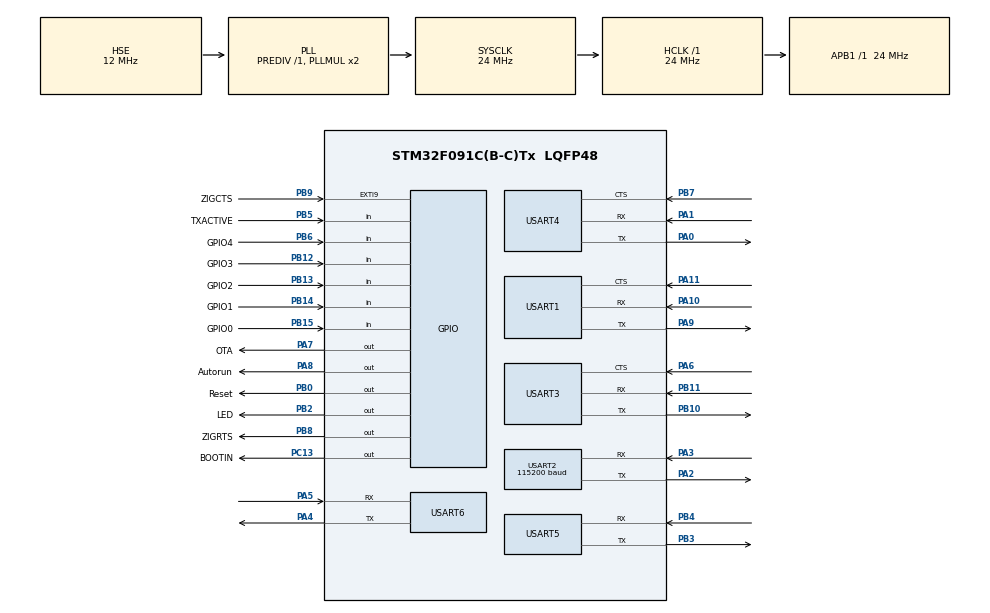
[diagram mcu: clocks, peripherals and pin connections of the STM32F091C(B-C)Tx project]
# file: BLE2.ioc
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Dma.Request0=USART1_RX
Dma.Request1=USART2_RX
Dma.Request10=USART3_TX
Dma.Request11=USART4_TX
Dma.Request2=USART3_RX
Dma.Request3=USART6_RX
Dma.Request4=USART5_RX
Dma.Request5=USART4_RX
Dma.Request6=USART6_TX
Dma.Request7=USART5_TX
Dma.Request8=USART1_TX
Dma.Request9=USART2_TX
Dma.USART1_RX.0.Direction=DMA_PERIPH_TO_MEMORY
Dma.USART1_RX.0.Instance=DMA1_Channel1
Dma.USART1_RX.0.MemDataAlignment=DMA_MDATAALIGN_BYTE
Dma.USART1_RX.0.MemInc=DMA_MINC_ENABLE
Dma.USART1_RX.0.Mode=DMA_CIRCULAR
Dma.USART1_RX.0.PeriphDataAlignment=DMA_PDATAALIGN_BYTE
Dma.USART1_RX.0.PeriphInc=DMA_PINC_DISABLE
Dma.USART1_RX.0.Priority=DMA_PRIORITY_LOW
Dma.USART1_TX.8.Direction=DMA_MEMORY_TO_PERIPH
Dma.USART1_TX.8.Instance=DMA1_Channel7
Dma.USART1_TX.8.MemDataAlignment=DMA_MDATAALIGN_BYTE
Dma.USART1_TX.8.MemInc=DMA_MINC_ENABLE
Dma.USART1_TX.8.Mode=DMA_NORMAL
Dma.USART1_TX.8.PeriphDataAlignment=DMA_PDATAALIGN_BYTE
Dma.USART1_TX.8.PeriphInc=DMA_PINC_DISABLE
Dma.USART1_TX.8.Priority=DMA_PRIORITY_LOW
Dma.USART2_RX.1.Direction=DMA_PERIPH_TO_MEMORY
Dma.USART2_RX.1.Instance=DMA1_Channel3
Dma.USART2_RX.1.MemDataAlignment=DMA_MDATAALIGN_BYTE
Dma.USART2_RX.1.MemInc=DMA_MINC_ENABLE
Dma.USART2_RX.1.Mode=DMA_CIRCULAR
Dma.USART2_RX.1.PeriphDataAlignment=DMA_PDATAALIGN_BYTE
Dma.USART2_RX.1.PeriphInc=DMA_PINC_DISABLE
Dma.USART2_RX.1.Priority=DMA_PRIORITY_LOW
Dma.USART2_TX.9.Direction=DMA_MEMORY_TO_PERIPH
Dma.USART2_TX.9.Instance=DMA2_Channel1
Dma.USART2_TX.9.MemDataAlignment=DMA_MDATAALIGN_BYTE
Dma.USART2_TX.9.MemInc=DMA_MINC_ENABLE
Dma.USART2_TX.9.Mode=DMA_NORMAL
Dma.USART2_TX.9.PeriphDataAlignment=DMA_PDATAALIGN_BYTE
Dma.USART2_TX.9.PeriphInc=DMA_PINC_DISABLE
Dma.USART2_TX.9.Priority=DMA_PRIORITY_LOW
Dma.USART3_RX.2.Direction=DMA_PERIPH_TO_MEMORY
Dma.USART3_RX.2.Instance=DMA1_Channel5
Dma.USART3_RX.2.MemDataAlignment=DMA_MDATAALIGN_BYTE
Dma.USART3_RX.2.MemInc=DMA_MINC_ENABLE
Dma.USART3_RX.2.Mode=DMA_CIRCULAR
Dma.USART3_RX.2.PeriphDataAlignment=DMA_PDATAALIGN_BYTE
Dma.USART3_RX.2.PeriphInc=DMA_PINC_DISABLE
Dma.USART3_RX.2.Priority=DMA_PRIORITY_LOW
Dma.USART3_TX.10.Direction=DMA_MEMORY_TO_PERIPH
Dma.USART3_TX.10.Instance=DMA2_Channel4
Dma.USART3_TX.10.MemDataAlignment=DMA_MDATAALIGN_BYTE
Dma.USART3_TX.10.MemInc=DMA_MINC_ENABLE
Dma.USART3_TX.10.Mode=DMA_NORMAL
Dma.USART3_TX.10.PeriphDataAlignment=DMA_PDATAALIGN_BYTE
Dma.USART3_TX.10.PeriphInc=DMA_PINC_DISABLE
Dma.USART3_TX.10.Priority=DMA_PRIORITY_LOW
Dma.USART4_RX.5.Direction=DMA_PERIPH_TO_MEMORY
Dma.USART4_RX.5.Instance=DMA2_Channel3
Dma.USART4_RX.5.MemDataAlignment=DMA_MDATAALIGN_BYTE
Dma.USART4_RX.5.MemInc=DMA_MINC_ENABLE
Dma.USART4_RX.5.Mode=DMA_CIRCULAR
Dma.USART4_RX.5.PeriphDataAlignment=DMA_PDATAALIGN_BYTE
Dma.USART4_RX.5.PeriphInc=DMA_PINC_DISABLE
Dma.USART4_RX.5.Priority=DMA_PRIORITY_LOW
Dma.USART4_TX.11.Direction=DMA_MEMORY_TO_PERIPH
Dma.USART4_TX.11.Instance=DMA2_Channel5
Dma.USART4_TX.11.MemDataAlignment=DMA_MDATAALIGN_BYTE
Dma.USART4_TX.11.MemInc=DMA_MINC_ENABLE
Dma.USART4_TX.11.Mode=DMA_NORMAL
Dma.USART4_TX.11.PeriphDataAlignment=DMA_PDATAALIGN_BYTE
Dma.USART4_TX.11.PeriphInc=DMA_PINC_DISABLE
Dma.USART4_TX.11.Priority=DMA_PRIORITY_LOW
Dma.USART5_RX.4.Direction=DMA_PERIPH_TO_MEMORY
Dma.USART5_RX.4.Instance=DMA2_Channel2
Dma.USART5_RX.4.MemDataAlignment=DMA_MDATAALIGN_BYTE
Dma.USART5_RX.4.MemInc=DMA_MINC_ENABLE
Dma.USART5_RX.4.Mode=DMA_CIRCULAR
Dma.USART5_RX.4.PeriphDataAlignment=DMA_PDATAALIGN_BYTE
Dma.USART5_RX.4.PeriphInc=DMA_PINC_DISABLE
Dma.USART5_RX.4.Priority=DMA_PRIORITY_LOW
Dma.USART5_TX.7.Direction=DMA_MEMORY_TO_PERIPH
Dma.USART5_TX.7.Instance=DMA1_Channel4
Dma.USART5_TX.7.MemDataAlignment=DMA_MDATAALIGN_BYTE
Dma.USART5_TX.7.MemInc=DMA_MINC_ENABLE
Dma.USART5_TX.7.Mode=DMA_NORMAL
Dma.USART5_TX.7.PeriphDataAlignment=DMA_PDATAALIGN_BYTE
Dma.USART5_TX.7.PeriphInc=DMA_PINC_DISABLE
Dma.USART5_TX.7.Priority=DMA_PRIORITY_LOW
Dma.USART6_RX.3.Direction=DMA_PERIPH_TO_MEMORY
Dma.USART6_RX.3.Instance=DMA1_Channel6
Dma.USART6_RX.3.MemDataAlignment=DMA_MDATAALIGN_BYTE
Dma.USART6_RX.3.MemInc=DMA_MINC_ENABLE
Dma.USART6_RX.3.Mode=DMA_CIRCULAR
Dma.USART6_RX.3.PeriphDataAlignment=DMA_PDATAALIGN_BYTE
Dma.USART6_RX.3.PeriphInc=DMA_PINC_DISABLE
Dma.USART6_RX.3.Priority=DMA_PRIORITY_LOW
Dma.USART6_TX.6.Direction=DMA_MEMORY_TO_PERIPH
Dma.USART6_TX.6.Instance=DMA1_Channel2
Dma.USART6_TX.6.MemDataAlignment=DMA_MDATAALIGN_BYTE
Dma.USART6_TX.6.MemInc=DMA_MINC_ENABLE
Dma.USART6_TX.6.Mode=DMA_NORMAL
Dma.USART6_TX.6.PeriphDataAlignment=DMA_PDATAALIGN_BYTE
Dma.USART6_TX.6.PeriphInc=DMA_PINC_DISABLE
Dma.USART6_TX.6.Priority=DMA_PRIORITY_LOW
Mcu.Family=STM32F0
Mcu.Name=STM32F091C(B-C)Tx
Mcu.Package=LQFP48
NVIC.DMA1_Ch1_IRQn=true\:0\:0\:false\:false\:true\:true
NVIC.DMA1_Ch2_3_DMA2_Ch1_2_IRQn=true\:0\:0\:false\:false\:true\:true
NVIC.DMA1_Ch4_7_DMA2_Ch3_5_IRQn=true\:0\:0\:false\:false\:true\:true
NVIC.USART1_IRQn=true\:0\:0\:false\:false\:true\:true
NVIC.USART2_IRQn=true\:0\:0\:false\:false\:true\:true
NVIC.USART3_8_IRQn=true\:0\:0\:false\:false\:true\:true
PA0.Mode=Asynchronous
PA0.Signal=USART4_TX
PA1.Mode=Asynchronous
PA1.Signal=USART4_RX
PA10.Mode=Asynchronous
PA10.Signal=USART1_RX
PA11.Mode=CTS_Only
PA11.Signal=USART1_CTS
PA13.Mode=Serial_Wire
PA13.Signal=SYS_SWDIO
PA14.Mode=Serial_Wire
PA14.Signal=SYS_SWCLK
PA2.Mode=Asynchronous
PA2.Signal=USART2_TX
PA3.Mode=Asynchronous
PA3.Signal=USART2_RX
PA4.Mode=Asynchronous
PA4.Signal=USART6_TX
PA5.Mode=Asynchronous
PA5.Signal=USART6_RX
PA6.Mode=CTS_Only
PA6.Signal=USART3_CTS
PA7.GPIO_Label=OTA
PA7.Signal=GPIO_Output
PA8.GPIO_Label=Autorun
PA8.Signal=GPIO_Output
PA9.Mode=Asynchronous
PA9.Signal=USART1_TX
PB0.GPIO_Label=Reset
PB0.Signal=GPIO_Output
PB10.Mode=Asynchronous
PB10.Signal=USART3_TX
PB11.Mode=Asynchronous
PB11.Signal=USART3_RX
PB12.GPIO_Label=GPIO3
PB12.Signal=GPIO_Input
PB13.GPIO_Label=GPIO2
PB13.Signal=GPIO_Input
PB14.GPIO_Label=GPIO1
PB14.Signal=GPIO_Input
PB15.GPIO_Label=GPIO0
PB15.Signal=GPIO_Input
PB2.GPIO_Label=LED
PB2.Signal=GPIO_Output
PB3.Mode=Asynchronous
PB3.Signal=USART5_TX
PB4.Mode=Asynchronous
PB4.Signal=USART5_RX
PB5.GPIO_Label=TXACTIVE
PB5.Signal=GPIO_Input
PB6.GPIO_Label=GPIO4
PB6.Signal=GPIO_Input
PB7.Mode=CTS_Only
PB7.Signal=USART4_CTS
PB8.GPIO_Label=ZIGRTS
PB8.Signal=GPIO_Output
PB9.GPIO_Label=ZIGCTS
PB9.Signal=GPXTI9
PC13.GPIO_Label=BOOTIN
PC13.Signal=GPIO_Output
PF0-OSC_IN.Mode=HSE-External-Oscillator
PF0-OSC_IN.Signal=RCC_OSC_IN
PF1-OSC_OUT.Mode=HSE-External-Oscillator
PF1-OSC_OUT.Signal=RCC_OSC_OUT
PF11BOOT0.Signal=GPIO_Input
ProjectManager.HeapSize=0x200
ProjectManager.StackSize=0x400
ProjectManager.TargetToolchain=MDK-ARM V5
RCC.AHBFreq_Value=24000000
RCC.APB1Freq_Value=24000000
RCC.APB1TimFreq_Value=24000000
RCC.HCLKFreq_Value=24000000
RCC.HSE_VALUE=12000000
RCC.PLLSourceVirtual=RCC_PLLSOURCE_HSE
RCC.SYSCLKFreq_VALUE=24000000
RCC.SYSCLKSource=RCC_SYSCLKSOURCE_PLLCLK
USART1.VirtualMode-Asynchronous=VM_ASYNC
USART2.BaudRate=115200
USART2.VirtualMode-Asynchronous=VM_ASYNC
USART3.VirtualMode-Asynchronous=VM_ASYNC
USART4.VirtualMode-Asynchronous=VM_ASYNC
USART5.VirtualMode-Asynchronous=VM_ASYNC
USART6.VirtualMode=VM_ASYNC
VP_RTC_VS_RTC_Activate.Mode=RTC_Enabled
board=custom

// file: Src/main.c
/* USER CODE BEGIN Header */
/**
  ******************************************************************************
  * @file           : main.c
  * @brief          : Main program body
  ******************************************************************************
  ** This notice applies to any and all portions of this file
  * that are not between comment pairs USER CODE BEGIN and
  * USER CODE END. Other portions of this file, whether
  * inserted by the user or by software development tools
  * are owned by their respective copyright owners.
  *
  * COPYRIGHT(c) 2018 STMicroelectronics
  *
  * Redistribution and use in source and binary forms, with or without modification,
  * are permitted provided that the following conditions are met:
  *   1. Redistributions of source code must retain the above copyright notice,
  *      this list of conditions and the following disclaimer.
  *   2. Redistributions in binary form must reproduce the above copyright notice,
  *      this list of conditions and the following disclaimer in the documentation
  *      and/or other materials provided with the distribution.
  *   3. Neither the name of STMicroelectronics nor the names of its contributors
  *      may be used to endorse or promote products derived from this software
  *      without specific prior written permission.
  *
  * THIS SOFTWARE IS PROVIDED BY THE COPYRIGHT HOLDERS AND CONTRIBUTORS "AS IS"
  * AND ANY EXPRESS OR IMPLIED WARRANTIES, INCLUDING, BUT NOT LIMITED TO, THE
  * IMPLIED WARRANTIES OF MERCHANTABILITY AND FITNESS FOR A PARTICULAR PURPOSE ARE
  * DISCLAIMED. IN NO EVENT SHALL THE COPYRIGHT HOLDER OR CONTRIBUTORS BE LIABLE
  * FOR ANY DIRECT, INDIRECT, INCIDENTAL, SPECIAL, EXEMPLARY, OR CONSEQUENTIAL
  * DAMAGES (INCLUDING, BUT NOT LIMITED TO, PROCUREMENT OF SUBSTITUTE GOODS OR
  * SERVICES; LOSS OF USE, DATA, OR PROFITS; OR BUSINESS INTERRUPTION) HOWEVER
  * CAUSED AND ON ANY THEORY OF LIABILITY, WHETHER IN CONTRACT, STRICT LIABILITY,
  * OR TORT (INCLUDING NEGLIGENCE OR OTHERWISE) ARISING IN ANY WAY OUT OF THE USE
  * OF THIS SOFTWARE, EVEN IF ADVISED OF THE POSSIBILITY OF SUCH DAMAGE.
  *
  ******************************************************************************
  */
/* USER CODE END Header */

#include "main.h"

/* USER CODE BEGIN Includes */
#include <stdbool.h>
#include <string.h>
#include "BLE.h"
#include "ZigBee.h"
#include "ServiceUartIF.h"

#pragma anon_unions
/* USER CODE END Includes */

RTC_HandleTypeDef hrtc;

UART_HandleTypeDef huart1;
UART_HandleTypeDef huart2;
UART_HandleTypeDef huart3;
UART_HandleTypeDef huart4;
UART_HandleTypeDef huart5;
UART_HandleTypeDef huart6;
DMA_HandleTypeDef hdma_usart1_rx;
DMA_HandleTypeDef hdma_usart1_tx;
DMA_HandleTypeDef hdma_usart2_rx;
DMA_HandleTypeDef hdma_usart2_tx;
DMA_HandleTypeDef hdma_usart3_rx;
DMA_HandleTypeDef hdma_usart3_tx;
DMA_HandleTypeDef hdma_usart4_rx;
DMA_HandleTypeDef hdma_usart4_tx;
DMA_HandleTypeDef hdma_usart5_rx;
DMA_HandleTypeDef hdma_usart5_tx;
DMA_HandleTypeDef hdma_usart6_rx;
DMA_HandleTypeDef hdma_usart6_tx;

void SystemClock_Config(void);
static void MX_GPIO_Init(void);
static void MX_DMA_Init(void);
static void MX_RTC_Init(void);
static void MX_USART1_UART_Init(void);
static void MX_USART2_UART_Init(void);
static void MX_USART3_UART_Init(void);
static void MX_USART4_UART_Init(void);
static void MX_USART5_UART_Init(void);
static void MX_USART6_UART_Init(void);

/* USER CODE BEGIN 0 */

//#define BUFFER_SIZE 256  /* must be power of two */
#define TX_BUFFER_SIZE 1024
//#define COMMAND_BUFFER_SIZE 128

void HAL_UART_ErrorCallback(UART_HandleTypeDef *huart)
{
    if(huart == &huart3)
    {
        if(huart->ErrorCode == HAL_UART_ERROR_FE)
        {
            __HAL_UART_CLEAR_FEFLAG(huart);
        }
    }

    if(huart == &huart2)
    {
        if(huart->ErrorCode == HAL_UART_ERROR_FE)
        {
            __HAL_UART_CLEAR_FEFLAG(huart);
        }
        ZigBeeReinitializeDMA();
    }
}

/* USER CODE END 0 */

int main(void)
{

  /* MCU Configuration--------------------------------------------------------*/

  /* Reset of all peripherals, Initializes the Flash interface and the Systick. */
  HAL_Init();

  /* Configure the system clock */
  SystemClock_Config();

  /* Initialize all configured peripherals */
  MX_GPIO_Init();
  MX_DMA_Init();
  MX_RTC_Init();
  MX_USART1_UART_Init();
  MX_USART2_UART_Init();
  MX_USART3_UART_Init();
  MX_USART4_UART_Init();
  MX_USART5_UART_Init();
  MX_USART6_UART_Init();
  /* USER CODE BEGIN 2 */

  HAL_GPIO_WritePin(BOOTIN_GPIO_Port, BOOTIN_Pin, GPIO_PIN_SET);    //do not boot in bootloader mode (RTX357)

  HAL_Delay(200);

  HAL_GPIO_WritePin(LED_GPIO_Port, LED_Pin, GPIO_PIN_SET);
  HAL_GPIO_WritePin(Reset_GPIO_Port, Reset_Pin, GPIO_PIN_SET);

  HAL_Delay(200);

  ServiceUartIFInit(&huart6);
  ZigBeeInit(&huart2);
  BleInit(&huart3, &huart1, &huart4, &huart5);

  /* USER CODE END 2 */

  /* Infinite loop */
  /* USER CODE BEGIN WHILE */
  //QueueItem *qi;

  while (1)
  {
    /* USER CODE END WHILE */

    /* USER CODE BEGIN 3 */
      BleTask();
      ZigBeeTask();
      ServiceUartIFTask();

  }
  /* USER CODE END 3 */
}

void SystemClock_Config(void)
{
  RCC_OscInitTypeDef RCC_OscInitStruct = {0};
  RCC_ClkInitTypeDef RCC_ClkInitStruct = {0};
  RCC_PeriphCLKInitTypeDef PeriphClkInit = {0};

  /**Initializes the CPU, AHB and APB busses clocks
  */
  RCC_OscInitStruct.OscillatorType = RCC_OSCILLATORTYPE_LSI|RCC_OSCILLATORTYPE_HSE;
  RCC_OscInitStruct.HSEState = RCC_HSE_ON;
  RCC_OscInitStruct.LSIState = RCC_LSI_ON;
  RCC_OscInitStruct.PLL.PLLState = RCC_PLL_ON;
  RCC_OscInitStruct.PLL.PLLSource = RCC_PLLSOURCE_HSE;
  RCC_OscInitStruct.PLL.PLLMUL = RCC_PLL_MUL2;
  RCC_OscInitStruct.PLL.PREDIV = RCC_PREDIV_DIV1;
  if (HAL_RCC_OscConfig(&RCC_OscInitStruct) != HAL_OK)
  {
    Error_Handler();
  }
  /**Initializes the CPU, AHB and APB busses clocks
  */
  RCC_ClkInitStruct.ClockType = RCC_CLOCKTYPE_HCLK|RCC_CLOCKTYPE_SYSCLK
                              |RCC_CLOCKTYPE_PCLK1;
  RCC_ClkInitStruct.SYSCLKSource = RCC_SYSCLKSOURCE_PLLCLK;
  RCC_ClkInitStruct.AHBCLKDivider = RCC_SYSCLK_DIV1;
  RCC_ClkInitStruct.APB1CLKDivider = RCC_HCLK_DIV1;

  if (HAL_RCC_ClockConfig(&RCC_ClkInitStruct, FLASH_LATENCY_0) != HAL_OK)
  {
    Error_Handler();
  }
  PeriphClkInit.PeriphClockSelection = RCC_PERIPHCLK_USART3|RCC_PERIPHCLK_USART1
                              |RCC_PERIPHCLK_USART2|RCC_PERIPHCLK_RTC;
  PeriphClkInit.Usart1ClockSelection = RCC_USART1CLKSOURCE_PCLK1;
  PeriphClkInit.Usart2ClockSelection = RCC_USART2CLKSOURCE_PCLK1;
  PeriphClkInit.Usart3ClockSelection = RCC_USART3CLKSOURCE_PCLK1;
  PeriphClkInit.RTCClockSelection = RCC_RTCCLKSOURCE_LSI;
  if (HAL_RCCEx_PeriphCLKConfig(&PeriphClkInit) != HAL_OK)
  {
    Error_Handler();
  }
}

static void MX_RTC_Init(void)
{

  /**Initialize RTC Only
  */
  hrtc.Instance = RTC;
  hrtc.Init.HourFormat = RTC_HOURFORMAT_24;
  hrtc.Init.AsynchPrediv = 127;
  hrtc.Init.SynchPrediv = 255;
  hrtc.Init.OutPut = RTC_OUTPUT_DISABLE;
  hrtc.Init.OutPutPolarity = RTC_OUTPUT_POLARITY_HIGH;
  hrtc.Init.OutPutType = RTC_OUTPUT_TYPE_OPENDRAIN;
  if (HAL_RTC_Init(&hrtc) != HAL_OK)
  {
    Error_Handler();
  }

}

static void MX_USART1_UART_Init(void)
{

  huart1.Instance = USART1;
  huart1.Init.BaudRate = 115200;
  huart1.Init.WordLength = UART_WORDLENGTH_8B;
  huart1.Init.StopBits = UART_STOPBITS_1;
  huart1.Init.Parity = UART_PARITY_NONE;
  huart1.Init.Mode = UART_MODE_TX_RX;
  huart1.Init.HwFlowCtl = UART_HWCONTROL_CTS;
  huart1.Init.OverSampling = UART_OVERSAMPLING_16;
  huart1.Init.OneBitSampling = UART_ONE_BIT_SAMPLE_DISABLE;
  huart1.AdvancedInit.AdvFeatureInit = UART_ADVFEATURE_NO_INIT;
  if (HAL_UART_Init(&huart1) != HAL_OK)
  {
    Error_Handler();
  }

}

static void MX_USART2_UART_Init(void)
{

  huart2.Instance = USART2;
  huart2.Init.BaudRate = 115200;
  huart2.Init.WordLength = UART_WORDLENGTH_8B;
  huart2.Init.StopBits = UART_STOPBITS_1;
  huart2.Init.Parity = UART_PARITY_NONE;
  huart2.Init.Mode = UART_MODE_TX_RX;
  huart2.Init.HwFlowCtl = UART_HWCONTROL_NONE;
  huart2.Init.OverSampling = UART_OVERSAMPLING_16;
  huart2.Init.OneBitSampling = UART_ONE_BIT_SAMPLE_DISABLE;
  huart2.AdvancedInit.AdvFeatureInit = UART_ADVFEATURE_NO_INIT;
  if (HAL_UART_Init(&huart2) != HAL_OK)
  {
    Error_Handler();
  }

}

static void MX_USART3_UART_Init(void)
{

  huart3.Instance = USART3;
  huart3.Init.BaudRate = 115200;
  huart3.Init.WordLength = UART_WORDLENGTH_8B;
  huart3.Init.StopBits = UART_STOPBITS_1;
  huart3.Init.Parity = UART_PARITY_NONE;
  huart3.Init.Mode = UART_MODE_TX_RX;
  huart3.Init.HwFlowCtl = UART_HWCONTROL_CTS;
  huart3.Init.OverSampling = UART_OVERSAMPLING_16;
  huart3.Init.OneBitSampling = UART_ONE_BIT_SAMPLE_DISABLE;
  huart3.AdvancedInit.AdvFeatureInit = UART_ADVFEATURE_NO_INIT;
  if (HAL_UART_Init(&huart3) != HAL_OK)
  {
    Error_Handler();
  }

}

static void MX_USART4_UART_Init(void)
{

  huart4.Instance = USART4;
  huart4.Init.BaudRate = 115200;
  huart4.Init.WordLength = UART_WORDLENGTH_8B;
  huart4.Init.StopBits = UART_STOPBITS_1;
  huart4.Init.Parity = UART_PARITY_NONE;
  huart4.Init.Mode = UART_MODE_TX_RX;
  huart4.Init.HwFlowCtl = UART_HWCONTROL_CTS;
  huart4.Init.OverSampling = UART_OVERSAMPLING_16;
  huart4.Init.OneBitSampling = UART_ONE_BIT_SAMPLE_DISABLE;
  huart4.AdvancedInit.AdvFeatureInit = UART_ADVFEATURE_NO_INIT;
  if (HAL_UART_Init(&huart4) != HAL_OK)
  {
    Error_Handler();
  }

}

static void MX_USART5_UART_Init(void)
{

  huart5.Instance = USART5;
  huart5.Init.BaudRate = 115200;
  huart5.Init.WordLength = UART_WORDLENGTH_8B;
  huart5.Init.StopBits = UART_STOPBITS_1;
  huart5.Init.Parity = UART_PARITY_NONE;
  huart5.Init.Mode = UART_MODE_TX_RX;
  huart5.Init.HwFlowCtl = UART_HWCONTROL_NONE;
  huart5.Init.OverSampling = UART_OVERSAMPLING_16;
  huart5.Init.OneBitSampling = UART_ONE_BIT_SAMPLE_DISABLE;
  huart5.AdvancedInit.AdvFeatureInit = UART_ADVFEATURE_NO_INIT;
  if (HAL_UART_Init(&huart5) != HAL_OK)
  {
    Error_Handler();
  }

}

static void MX_USART6_UART_Init(void)
{

  huart6.Instance = USART6;
  huart6.Init.BaudRate = 115200;
  huart6.Init.WordLength = UART_WORDLENGTH_8B;
  huart6.Init.StopBits = UART_STOPBITS_1;
  huart6.Init.Parity = UART_PARITY_NONE;
  huart6.Init.Mode = UART_MODE_TX_RX;
  huart6.Init.HwFlowCtl = UART_HWCONTROL_NONE;
  huart6.Init.OverSampling = UART_OVERSAMPLING_16;
  huart6.Init.OneBitSampling = UART_ONE_BIT_SAMPLE_DISABLE;
  huart6.AdvancedInit.AdvFeatureInit = UART_ADVFEATURE_NO_INIT;
  if (HAL_UART_Init(&huart6) != HAL_OK)
  {
    Error_Handler();
  }

}

static void MX_DMA_Init(void)
{
  /* DMA controller clock enable */
  __HAL_RCC_DMA1_CLK_ENABLE();
  __HAL_RCC_DMA2_CLK_ENABLE();

  /* DMA interrupt init */
  /* DMA1_Ch1_IRQn interrupt configuration */
  HAL_NVIC_SetPriority(DMA1_Ch1_IRQn, 0, 0);
  HAL_NVIC_EnableIRQ(DMA1_Ch1_IRQn);
  /* DMA1_Ch2_3_DMA2_Ch1_2_IRQn interrupt configuration */
  HAL_NVIC_SetPriority(DMA1_Ch2_3_DMA2_Ch1_2_IRQn, 0, 0);
  HAL_NVIC_EnableIRQ(DMA1_Ch2_3_DMA2_Ch1_2_IRQn);
  /* DMA1_Ch4_7_DMA2_Ch3_5_IRQn interrupt configuration */
  HAL_NVIC_SetPriority(DMA1_Ch4_7_DMA2_Ch3_5_IRQn, 0, 0);
  HAL_NVIC_EnableIRQ(DMA1_Ch4_7_DMA2_Ch3_5_IRQn);

}

static void MX_GPIO_Init(void)
{
  GPIO_InitTypeDef GPIO_InitStruct = {0};

  /* GPIO Ports Clock Enable */
  __HAL_RCC_GPIOC_CLK_ENABLE();
  __HAL_RCC_GPIOF_CLK_ENABLE();
  __HAL_RCC_GPIOA_CLK_ENABLE();
  __HAL_RCC_GPIOB_CLK_ENABLE();

  /*Configure GPIO pin Output Level */
  HAL_GPIO_WritePin(BOOTIN_GPIO_Port, BOOTIN_Pin, GPIO_PIN_RESET);

  /*Configure GPIO pin Output Level */
  HAL_GPIO_WritePin(GPIOA, OTA_Pin|Autorun_Pin, GPIO_PIN_RESET);

  /*Configure GPIO pin Output Level */
  HAL_GPIO_WritePin(GPIOB, Reset_Pin|LED_Pin|ZIGRTS_Pin, GPIO_PIN_RESET);

  /*Configure GPIO pin : BOOTIN_Pin */
  GPIO_InitStruct.Pin = BOOTIN_Pin;
  GPIO_InitStruct.Mode = GPIO_MODE_OUTPUT_PP;
  GPIO_InitStruct.Pull = GPIO_NOPULL;
  GPIO_InitStruct.Speed = GPIO_SPEED_FREQ_LOW;
  HAL_GPIO_Init(BOOTIN_GPIO_Port, &GPIO_InitStruct);

  /*Configure GPIO pins : PC14 PC15 */
  GPIO_InitStruct.Pin = GPIO_PIN_14|GPIO_PIN_15;
  GPIO_InitStruct.Mode = GPIO_MODE_ANALOG;
  GPIO_InitStruct.Pull = GPIO_NOPULL;
  HAL_GPIO_Init(GPIOC, &GPIO_InitStruct);

  /*Configure GPIO pins : OTA_Pin Autorun_Pin */
  GPIO_InitStruct.Pin = OTA_Pin|Autorun_Pin;
  GPIO_InitStruct.Mode = GPIO_MODE_OUTPUT_PP;
  GPIO_InitStruct.Pull = GPIO_NOPULL;
  GPIO_InitStruct.Speed = GPIO_SPEED_FREQ_LOW;
  HAL_GPIO_Init(GPIOA, &GPIO_InitStruct);

  /*Configure GPIO pins : Reset_Pin LED_Pin ZIGRTS_Pin */
  GPIO_InitStruct.Pin = Reset_Pin|LED_Pin|ZIGRTS_Pin;
  GPIO_InitStruct.Mode = GPIO_MODE_OUTPUT_PP;
  GPIO_InitStruct.Pull = GPIO_NOPULL;
  GPIO_InitStruct.Speed = GPIO_SPEED_FREQ_LOW;
  HAL_GPIO_Init(GPIOB, &GPIO_InitStruct);

  /*Configure GPIO pin : PB1 */
  GPIO_InitStruct.Pin = GPIO_PIN_1;
  GPIO_InitStruct.Mode = GPIO_MODE_ANALOG;
  GPIO_InitStruct.Pull = GPIO_NOPULL;
  HAL_GPIO_Init(GPIOB, &GPIO_InitStruct);

  /*Configure GPIO pins : GPIO3_Pin GPIO2_Pin GPIO1_Pin GPIO0_Pin
                           TXACTIVE_Pin GPIO4_Pin */
  GPIO_InitStruct.Pin = GPIO3_Pin|GPIO2_Pin|GPIO1_Pin|GPIO0_Pin
                          |TXACTIVE_Pin|GPIO4_Pin;
  GPIO_InitStruct.Mode = GPIO_MODE_INPUT;
  GPIO_InitStruct.Pull = GPIO_NOPULL;
  HAL_GPIO_Init(GPIOB, &GPIO_InitStruct);

  /*Configure GPIO pins : PA12 PA15 */
  GPIO_InitStruct.Pin = GPIO_PIN_12|GPIO_PIN_15;
  GPIO_InitStruct.Mode = GPIO_MODE_ANALOG;
  GPIO_InitStruct.Pull = GPIO_NOPULL;
  HAL_GPIO_Init(GPIOA, &GPIO_InitStruct);

  /*Configure GPIO pin : PF11 */
  GPIO_InitStruct.Pin = GPIO_PIN_11;
  GPIO_InitStruct.Mode = GPIO_MODE_INPUT;
  GPIO_InitStruct.Pull = GPIO_NOPULL;
  HAL_GPIO_Init(GPIOF, &GPIO_InitStruct);

  /*Configure GPIO pin : ZIGCTS_Pin */
  GPIO_InitStruct.Pin = ZIGCTS_Pin;
  GPIO_InitStruct.Mode = GPIO_MODE_IT_RISING;
  GPIO_InitStruct.Pull = GPIO_NOPULL;
  HAL_GPIO_Init(ZIGCTS_GPIO_Port, &GPIO_InitStruct);

}

void Error_Handler(void)
{
}

/************************ (C) COPYRIGHT STMicroelectronics *****END OF FILE****/
